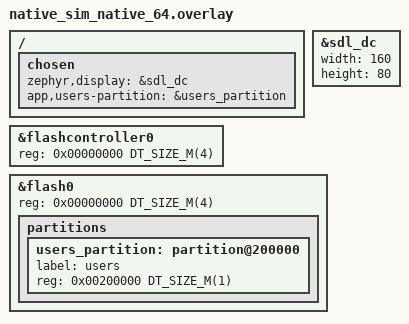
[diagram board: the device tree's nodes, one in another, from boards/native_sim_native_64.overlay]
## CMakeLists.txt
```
# SPDX-License-Identifier: Apache-2.0
cmake_minimum_required(VERSION 3.20.0)

# In-house libraries (gzm/): a Zephyr module that lives in this repository.
list(APPEND ZEPHYR_EXTRA_MODULES ${CMAKE_CURRENT_SOURCE_DIR}/../gzm)

find_package(Zephyr REQUIRED HINTS $ENV{ZEPHYR_BASE})
project(conferencia2026_demo LANGUAGES C)

target_include_directories(app PRIVATE inc)

target_sources(app PRIVATE
  src/main.c
  src/setup.c
  src/users_app.c
  src/ui_app.c
  src/images/gzm_logo_160.c
)

target_sources_ifdef(CONFIG_MCUBOOT_IMG_MANAGER app PRIVATE
  src/boot/boot.c
  src/boot/boot_shell.c
)
```

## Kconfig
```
# Copyright (c) 2026 GZM Embarcados
# SPDX-License-Identifier: Apache-2.0

mainmenu "Do Codigo ao Campo demo"

source "Kconfig.zephyr"

config APP_ADMIN_ID
	int "Default admin id (created on the first boot)"
	default 1

config APP_ADMIN_PASSWORD
	string "Default admin password (first boot only)"
	default "1234"
	help
	  Demo value, known by the Robot Framework suite. A product sets a
	  per-device password at the factory.
```

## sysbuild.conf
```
# Sysbuild configuration file.

# Enable MCUboot bootloader
SB_CONFIG_BOOTLOADER_MCUBOOT=y

# MCUboot upgrade mode: SWAP using scratch partition.
# Supports different sector sizes between slots (internal 128 KB vs
# external QSPI NOR 4 KB) and enables automatic rollback.
SB_CONFIG_MCUBOOT_MODE_SWAP_SCRATCH=y

# Signed images (ECDSA P-256). Demo key generated locally by
# tools/keys/genkeys.sh. Never commit a production key.
SB_CONFIG_BOOT_SIGNATURE_TYPE_ECDSA_P256=y
SB_CONFIG_BOOT_SIGNATURE_KEY_FILE="${APP_DIR}/../tools/keys/demo-ecdsa-p256.pem"

# Image encryption (ECIES P-256): the image stored in slot1 (external
# QSPI NOR) travels and rests encrypted; MCUboot decrypts during swap.
SB_CONFIG_BOOT_ENCRYPTION=y
SB_CONFIG_BOOT_ENCRYPTION_KEY_FILE="${APP_DIR}/../tools/keys/demo-encryption-p256.pem"
```

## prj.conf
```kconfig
CONFIG_SHELL=y
CONFIG_SHELL_STACK_SIZE=4096
CONFIG_LOG=y
CONFIG_LOG_MODE_DEFERRED=y

# === Display + LVGL ===
CONFIG_DISPLAY=y
CONFIG_LVGL=y
CONFIG_LV_CONF_MINIMAL=y
CONFIG_LV_Z_MEM_POOL_SIZE=16384
CONFIG_LV_USE_LABEL=y
CONFIG_LV_USE_IMAGE=y
CONFIG_LV_USE_BAR=y
# LV_CONF_MINIMAL ships without a theme; without one, default bg_opa is
# transparent and NOTHING gets filled (screens included). Enable the
# default theme in dark mode.
CONFIG_LV_USE_THEME_DEFAULT=y
CONFIG_LV_THEME_DEFAULT_DARK=y
CONFIG_LV_FONT_MONTSERRAT_12=y
CONFIG_LV_FONT_MONTSERRAT_14=y
CONFIG_LV_FONT_MONTSERRAT_24=y
CONFIG_LV_FONT_DEFAULT_MONTSERRAT_14=y


# === User store: gzm user_mgr on LittleFS (gzm/ module) ===
CONFIG_FLASH=y
CONFIG_FLASH_MAP=y
CONFIG_FLASH_PAGE_LAYOUT=y
CONFIG_FILE_SYSTEM=y
CONFIG_FILE_SYSTEM_LITTLEFS=y
CONFIG_FILE_SYSTEM_MKFS=y
CONFIG_PSA_CRYPTO=y
CONFIG_ENTROPY_GENERATOR=y
CONFIG_GZM_USER_MGR=y
CONFIG_GZM_USER_MGR_SHELL=y
# Product rule: at most 50 users, the default admin included
CONFIG_GZM_USER_MGR_MAX=50
# "fs ls /lfs/users", "fs cat …": look at the files behind the users
CONFIG_FILE_SYSTEM_SHELL=y
CONFIG_HEAP_MEM_POOL_SIZE=16384

# === Misc ===
CONFIG_MAIN_STACK_SIZE=8192
CONFIG_PRINTK=y
```

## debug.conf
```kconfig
# Debug options, loaded by every build (tasks "West Build" and "Native Build").
# Off by default, so the image you flash or update is the release one.
# Uncomment to debug: the next build picks the change up, no pristine needed.

# -Og instead of -Os: stepping follows the code and no <optimized out>
# CONFIG_DEBUG_OPTIMIZATIONS=y

# Thread list in the debugger (cortex-debug "rtos": "Zephyr"). Needs a gdb
# server with Zephyr support (OpenOCD, J-Link, pyOCD): the ST-LINK_gdbserver
# used here has none, so with ST-Link this option does nothing
# CONFIG_DEBUG_THREAD_INFO=y
```

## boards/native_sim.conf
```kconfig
# native_sim: LVGL UI in an SDL window on the host. No USB/MCUboot.
CONFIG_LV_COLOR_16_SWAP=n

# User store on the simulated flash (RAM-backed NOR).
CONFIG_FLASH_SIMULATOR=y
```

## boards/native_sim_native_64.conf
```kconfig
# native_sim 64-bit: LVGL UI in an SDL window on the host.
CONFIG_LV_COLOR_16_SWAP=n
# Match the LVGL 16-bit render pipeline (default ARGB8888 leaves the
# window on the transparency grid).
CONFIG_SDL_DISPLAY_DEFAULT_PIXEL_FORMAT_RGB_565=y
# Bigger window for screencasts (160x80 panel shown at 2x).
CONFIG_SDL_DISPLAY_ZOOM_PCT=200

# User store on the simulated flash (RAM-backed NOR).
CONFIG_FLASH_SIMULATOR=y
```

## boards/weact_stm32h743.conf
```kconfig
# WeAct MiniSTM32H743 specific configuration (auto-loaded by Zephyr
# alongside prj.conf when building for this board).

# Console/shell over USB CDC ACM (device stack next)
CONFIG_USB_DEVICE_STACK_NEXT=y
CONFIG_USBD_CDC_ACM_CLASS=y
CONFIG_UART_LINE_CTRL=y

# The ST7735R takes RGB565 big-endian over SPI. LVGL renders little-endian
# and byte-swaps the buffer right before flush when LV_COLOR_16_SWAP is set
# (compat hook in lv_refr.c). The board defaults it to y - keep it that way.
CONFIG_LV_COLOR_16_SWAP=y

# MCUboot integration (image state, confirm, slot info)
CONFIG_STREAM_FLASH=y
CONFIG_IMG_MANAGER=y
CONFIG_MCUBOOT_IMG_MANAGER=y
CONFIG_REBOOT=y

# Link the application at slot0 (requires --sysbuild builds)
CONFIG_USE_DT_CODE_PARTITION=y

# Keep feeding the IWDG started by MCUboot (see src/main.c)
CONFIG_WATCHDOG=y

# Keep SWD reachable while the core sleeps in the idle thread (WFI).
# Off by default outside CONFIG_DEBUG builds; without it the ST-Link cannot
# attach to the running app (no NRST wired for connect-under-reset).
CONFIG_STM32_ENABLE_DEBUG_SLEEP_STOP=y

# User store: LittleFS with 4 KB blocks (the W25Q64 sector) instead of the
# default 64 KB layout: much faster erases on every user add/delete.
CONFIG_SPI_NOR_FLASH_LAYOUT_PAGE_SIZE=4096
```

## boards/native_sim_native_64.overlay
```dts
/* Demo UI on the host: SDL display window with the panel geometry, and
 * the user store (LittleFS) on the flash simulator. The stock storage
 * partition is only 16 KB: grow the simulated flash to 4 MB and give the
 * users a 1 MB partition after the default layout. */

/ {
	chosen {
		zephyr,display = &sdl_dc;
		app,users-partition = &users_partition;
	};
};

&sdl_dc {
	width = <160>;
	height = <80>;
};

&flashcontroller0 {
	reg = <0x00000000 DT_SIZE_M(4)>;
};

&flash0 {
	reg = <0x00000000 DT_SIZE_M(4)>;

	partitions {
		users_partition: partition@200000 {
			label = "users";
			reg = <0x00200000 DT_SIZE_M(1)>;
		};
	};
};
```

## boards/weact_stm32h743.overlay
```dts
/*
 * Application overlay:
 * - user store (LittleFS) on the SPI NOR (W25Q64, storage_partition)
 * - application image linked into slot0 (MCUboot primary)
 */

/ {
	chosen {
		zephyr,code-partition = &slot0_partition;
		app,users-partition = &storage_partition;
	};
};
```

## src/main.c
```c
/* Copyright (c) 2026 GZM Embarcados
 * SPDX-License-Identifier: Apache-2.0
 */

#include <zephyr/drivers/watchdog.h>
#include <zephyr/kernel.h>
#include <lvgl.h>

#include "setup.h"

/* MCUboot starts the IWDG (20 s) and it cannot be stopped: the main loop
 * must keep feeding it. */
#if defined(CONFIG_WATCHDOG) && DT_NODE_HAS_STATUS(DT_ALIAS(watchdog0), okay)
static const struct device *const wdt = DEVICE_DT_GET(DT_ALIAS(watchdog0));
#define WDT_FEED() wdt_feed(wdt, 0)
#else
#define WDT_FEED()
#endif

int main(void)
{
	setup_init();

	while (1) {
		uint32_t sleep_ms = lv_timer_handler();

		WDT_FEED();
		k_msleep(MIN(sleep_ms, 50U));
	}

	return 0;
}
```

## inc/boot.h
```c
/* Copyright (c) 2026 GZM Embarcados
 * SPDX-License-Identifier: Apache-2.0
 */

#ifndef APP_BOOT_H_
#define APP_BOOT_H_

#ifdef __cplusplus
extern "C" {
#endif

#include <stdint.h>
#include <stdbool.h>

struct boot_slot_info {
	int slot;
	uint32_t offset;
	uint32_t size;
	uint32_t image_size;
	uint8_t version_major;
	uint8_t version_minor;
	uint16_t version_revision;
	uint32_t version_build;
	uint8_t hash[32];          /* SHA256 from the image TLV */
	char label[24];
	bool valid_header;
	bool has_hash;
	bool confirmed;            /* slot0: image confirmed */
	bool active;               /* slot0: running image */
	bool pending;              /* slot1: upgrade pending */
};

int boot_get_slot_count(void);

/** @brief Confirm the running image if it is not confirmed yet. */
void boot_check_and_confirm_image(void);

bool boot_is_image_confirmed(void);

int boot_erase_slot1(void);

/** @brief Fill @p info with header/flags/hash of the given slot. */
int boot_get_slot_info(int slot, struct boot_slot_info *info);

#ifdef __cplusplus
}
#endif

#endif /* APP_BOOT_H_ */
```

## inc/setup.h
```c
/* Copyright (c) 2026 GZM Embarcados
 * SPDX-License-Identifier: Apache-2.0
 */

#ifndef APP_SETUP_H_
#define APP_SETUP_H_

#ifdef __cplusplus
extern "C" {
#endif

/** @brief Bring up USB, the user store and the UI; a failing step is
 *  logged and boot continues. */
void setup_init(void);

#ifdef __cplusplus
}
#endif

#endif /* APP_SETUP_H_ */
```

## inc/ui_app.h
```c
/* Copyright (c) 2026 GZM Embarcados
 * SPDX-License-Identifier: Apache-2.0
 */

#ifndef APP_UI_APP_H_
#define APP_UI_APP_H_

#ifdef __cplusplus
extern "C" {
#endif

#include <stdint.h>

/**
 * Build the splash and main screens. The firmware major version picks the
 * colors: odd = white splash bar and black main screen, even = yellow.
 */
int ui_app_init(uint8_t fw_major);

#ifdef __cplusplus
}
#endif

#endif /* APP_UI_APP_H_ */
```

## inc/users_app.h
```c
/* Copyright (c) 2026 GZM Embarcados
 * SPDX-License-Identifier: Apache-2.0
 */

#ifndef APP_USERS_APP_H_
#define APP_USERS_APP_H_

#include <stdbool.h>
#include <stddef.h>

#ifdef __cplusplus
extern "C" {
#endif

/** @brief Mount LittleFS and load the user store (gzm user_mgr). */
int users_app_init(void);

bool users_app_ready(void);

/** @brief Registered users, the default admin included. */
size_t users_app_count(void);

size_t users_app_blocked(void);

#ifdef __cplusplus
}
#endif

#endif /* APP_USERS_APP_H_ */
```

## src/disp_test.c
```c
/* Copyright (c) 2026 GZM Embarcados
 * SPDX-License-Identifier: Apache-2.0
 *
 * Fills the panel through the display API, bypassing LVGL: separates panel
 * or byte-order problems from LVGL rendering problems.
 */

#include <zephyr/device.h>
#include <zephyr/drivers/display.h>
#include <zephyr/shell/shell.h>
#include <zephyr/sys/byteorder.h>

#include <stdlib.h>
#include <string.h>

#define DISP_W 160
#define DISP_H 80
#define STRIP_H 8

static uint16_t strip[DISP_W * STRIP_H];

struct color_map {
	const char *name;
	uint16_t rgb565; /* natural value, R in the top bits */
};

static const struct color_map colors[] = {
	{ "red",   0xF800 }, { "green", 0x07E0 }, { "blue",  0x001F },
	{ "white", 0xFFFF }, { "black", 0x0000 }, { "gray",  0x39C7 },
};

static int fill(const struct shell *shell, const char *name, bool swap)
{
	const struct device *disp = DEVICE_DT_GET(DT_CHOSEN(zephyr_display));
	const struct color_map *c = NULL;

	for (size_t i = 0; i < ARRAY_SIZE(colors); i++) {
		if (strcmp(name, colors[i].name) == 0) {
			c = &colors[i];
			break;
		}
	}
	if (c == NULL) {
		shell_error(shell, "colors: red green blue white black gray");
		return -EINVAL;
	}
	if (!device_is_ready(disp)) {
		shell_error(shell, "display not ready");
		return -ENODEV;
	}

	/* Panel wire order is big-endian; "fillswap" sends CPU-native LE. */
	uint16_t v = swap ? c->rgb565 : sys_cpu_to_be16(c->rgb565);

	for (size_t i = 0; i < ARRAY_SIZE(strip); i++) {
		strip[i] = v;
	}

	struct display_buffer_descriptor desc = {
		.buf_size = sizeof(strip),
		.width = DISP_W,
		.height = STRIP_H,
		.pitch = DISP_W,
	};

	for (int y = 0; y < DISP_H; y += STRIP_H) {
		int ret = display_write(disp, 0, y, &desc, strip);

		if (ret) {
			shell_error(shell, "display_write: %d", ret);
			return ret;
		}
	}

	shell_print(shell, "filled %s%s (0x%04x)", name,
		    swap ? " (swapped)" : "", v);
	return 0;
}

static int cmd_fill(const struct shell *shell, size_t argc, char **argv)
{
	if (argc != 2) {
		shell_error(shell, "Usage: disp fill <color>");
		return -EINVAL;
	}
	return fill(shell, argv[1], false);
}

static int cmd_fillswap(const struct shell *shell, size_t argc, char **argv)
{
	if (argc != 2) {
		shell_error(shell, "Usage: disp fillswap <color>");
		return -EINVAL;
	}
	return fill(shell, argv[1], true);
}

SHELL_STATIC_SUBCMD_SET_CREATE(sub_disp,
	SHELL_CMD(fill, NULL, "Fill screen via display API (no LVGL)", cmd_fill),
	SHELL_CMD(fillswap, NULL, "Fill with byte-swapped color", cmd_fillswap),
	SHELL_SUBCMD_SET_END);

SHELL_CMD_REGISTER(disp, &sub_disp, "Raw display tests", NULL);
```

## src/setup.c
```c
/* Copyright (c) 2026 GZM Embarcados
 * SPDX-License-Identifier: Apache-2.0
 */

#include <zephyr/device.h>
#include <zephyr/kernel.h>
#include <zephyr/usb/usbd.h>

#include <app_version.h>

#include "setup.h"
#include "ui_app.h"
#include "users_app.h"

#include <zephyr/logging/log.h>
LOG_MODULE_REGISTER(setup, CONFIG_LOG_DEFAULT_LEVEL);

#ifdef CONFIG_USB_DEVICE_STACK_NEXT
USBD_DEVICE_DEFINE(usbd_device,
		   DEVICE_DT_GET(DT_NODELABEL(usbotg_fs)),
		   0x1209, 0x0001);

USBD_DESC_LANG_DEFINE(usb_lang);
USBD_DESC_MANUFACTURER_DEFINE(usb_mfr, "GZM Embedded Systems");
USBD_DESC_PRODUCT_DEFINE(usb_product, "Do Codigo ao Campo Demo");
USBD_DESC_CONFIG_DEFINE(usb_fs_cfg_desc, "FS Configuration");

USBD_CONFIGURATION_DEFINE(usb_fs_config, USB_SCD_SELF_POWERED, 100, &usb_fs_cfg_desc);
#endif /* CONFIG_USB_DEVICE_STACK_NEXT */

static void setup_sanity_init(void)
{
	printk("Do Codigo ao Campo demo v%s\r\n", APP_VERSION_STRING);
}

static int setup_usb_init(void)
{
#ifndef CONFIG_USB_DEVICE_STACK_NEXT
	return 0;
#else
	int ret;

	ret = usbd_add_descriptor(&usbd_device, &usb_lang);
	if (ret) {
		LOG_ERR("USB lang descriptor: %d", ret);
		return ret;
	}

	ret = usbd_add_descriptor(&usbd_device, &usb_mfr);
	if (ret) {
		LOG_ERR("USB mfr descriptor: %d", ret);
		return ret;
	}

	ret = usbd_add_descriptor(&usbd_device, &usb_product);
	if (ret) {
		LOG_ERR("USB product descriptor: %d", ret);
		return ret;
	}

	ret = usbd_add_configuration(&usbd_device, USBD_SPEED_FS, &usb_fs_config);
	if (ret) {
		LOG_ERR("USB FS config: %d", ret);
		return ret;
	}

	ret = usbd_register_all_classes(&usbd_device, USBD_SPEED_FS, 1, NULL);
	if (ret) {
		LOG_ERR("USB register classes: %d", ret);
		return ret;
	}

	usbd_device_set_code_triple(&usbd_device, USBD_SPEED_FS,
				    USB_BCC_MISCELLANEOUS, 0x02, 0x01);

	ret = usbd_init(&usbd_device);
	if (ret) {
		LOG_ERR("usbd_init: %d", ret);
		return ret;
	}

	ret = usbd_enable(&usbd_device);
	if (ret) {
		LOG_ERR("usbd_enable: %d", ret);
		return ret;
	}

	return 0;
#endif /* CONFIG_USB_DEVICE_STACK_NEXT */
}

void setup_init(void)
{
	int ret;

	setup_sanity_init();

	ret = setup_usb_init();
	if (ret) {
		LOG_ERR("USB console init failed: %d", ret);
	}

	ret = users_app_init();
	if (ret) {
		LOG_ERR("users_app init failed: %d", ret);
	}

	ret = ui_app_init(APP_VERSION_MAJOR);
	if (ret) {
		LOG_ERR("ui_app init failed: %d", ret);
	}

	LOG_INF("setup done");
}
```

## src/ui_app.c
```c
/* Copyright (c) 2026 GZM Embarcados
 * SPDX-License-Identifier: Apache-2.0
 */

#include <lvgl.h>
#include <stdio.h>
#include <zephyr/device.h>
#include <zephyr/drivers/display.h>
#include <zephyr/drivers/gpio.h>
#include <string.h>
#include <zephyr/shell/shell.h>

#include <app_version.h>

#include "boot.h"
#include "ui_app.h"
#include "users_app.h"

#include <zephyr/logging/log.h>
LOG_MODULE_REGISTER(ui_app, CONFIG_LOG_DEFAULT_LEVEL);

#define UI_REFRESH_MS 200
#define UI_SPLASH_MS  3000

LV_IMAGE_DECLARE(gzm_logo_160);

static lv_obj_t *label_users;
static lv_obj_t *label_blocked;
static lv_obj_t *label_version;
static lv_obj_t *splash_bar;
static uint32_t splash_start;

#if DT_NODE_HAS_PROP(DT_PATH(zephyr_user), backlight_gpios)
static const struct gpio_dt_spec backlight =
	GPIO_DT_SPEC_GET(DT_PATH(zephyr_user), backlight_gpios);
#endif

/* Shell requests are applied from the LVGL timer context: LVGL is not
 * thread-safe. */
enum ui_request { UI_REQ_NONE, UI_REQ_PATTERN, UI_REQ_LOGO, UI_REQ_MAIN };
static volatile enum ui_request ui_request;

static void ui_main_create(void);

/* The firmware major version picks the colors (see ui_app_init), so an
 * update between an odd and an even version is visible at a glance. On
 * yellow the texts switch to dark tones to stay readable. */
struct ui_theme {
	uint32_t splash_bar;
	uint32_t main_bg;
	uint32_t title;
	uint32_t caption;
	uint32_t value;
	uint32_t value_full;
	uint32_t blocked;
	uint32_t confirmed;
	uint32_t testing;
};

static const struct ui_theme theme_odd = {
	.splash_bar = 0xffffff, .main_bg = 0x101418, .title = 0x80d8ff,
	.caption = 0x9e9e9e, .value = 0xffffff, .value_full = 0xff8a80,
	.blocked = 0xffab00, .confirmed = 0x00c853, .testing = 0xffab00,
};

static const struct ui_theme theme_even = {
	.splash_bar = 0xffd600, .main_bg = 0xffd600, .title = 0x0d47a1,
	.caption = 0x424242, .value = 0x101418, .value_full = 0xb71c1c,
	.blocked = 0xbf360c, .confirmed = 0x1b5e20, .testing = 0xbf360c,
};

static const struct ui_theme *theme = &theme_odd;

static void ui_refresh_cb(lv_timer_t *timer)
{
	ARG_UNUSED(timer);
	char text[32];

	if (label_users == NULL || label_blocked == NULL || label_version == NULL) {
		return;
	}

	if (users_app_ready()) {
		size_t n = users_app_count();
		size_t blocked = users_app_blocked();

		snprintf(text, sizeof(text), "%zu/%d", n, CONFIG_GZM_USER_MGR_MAX);
		lv_label_set_text(label_users, text);
		/* Full store: the next "user add" is refused (-ENOSPC). */
		lv_obj_set_style_text_color(label_users,
					    lv_color_hex(n >= CONFIG_GZM_USER_MGR_MAX
								 ? theme->value_full
								 : theme->value),
					    LV_PART_MAIN);
		snprintf(text, sizeof(text), "%zu", blocked);
		lv_label_set_text(label_blocked, text);
	} else {
		lv_label_set_text(label_users, "--");
		lv_label_set_text(label_blocked, "--");
	}

#ifdef CONFIG_MCUBOOT_IMG_MANAGER
	/* Reading the state goes to flash: once confirmed it cannot revert until
	 * the next boot, so stop polling; while in test, poll once per second. */
	static bool confirmed;
	static uint32_t polls;

	if (!confirmed && (polls++ % (1000 / UI_REFRESH_MS)) == 0) {
		confirmed = boot_is_image_confirmed();
	}
	const char *state = confirmed ? "OK" : "TEST";
	lv_color_t color = lv_color_hex(confirmed ? theme->confirmed : theme->testing);
#else
	const char *state = "SIM";
	lv_color_t color = lv_color_hex(theme->title);
#endif

	snprintf(text, sizeof(text), "v%s %s", APP_VERSION_STRING, state);
	lv_label_set_text(label_version, text);
	lv_obj_set_style_text_color(label_version, color, LV_PART_MAIN);
}

static void ui_main_create(void)
{
	lv_obj_t *screen = lv_screen_active();

	lv_obj_set_style_bg_opa(screen, LV_OPA_COVER, LV_PART_MAIN);

	lv_obj_t *title = lv_label_create(screen);

	lv_label_set_text(title, "DO CODIGO AO CAMPO");
	lv_obj_set_style_text_font(title, &lv_font_montserrat_12, LV_PART_MAIN);
	lv_obj_set_style_text_color(title, lv_color_hex(theme->title), LV_PART_MAIN);
	lv_obj_align(title, LV_ALIGN_TOP_MID, 0, 2);

	lv_obj_t *cap_users = lv_label_create(screen);

	lv_label_set_text(cap_users, "usuarios");
	lv_obj_set_style_text_font(cap_users, &lv_font_montserrat_12, LV_PART_MAIN);
	lv_obj_set_style_text_color(cap_users, lv_color_hex(theme->caption), LV_PART_MAIN);
	lv_obj_align(cap_users, LV_ALIGN_LEFT_MID, 8, -16);

	label_users = lv_label_create(screen);
	lv_label_set_text(label_users, "--");
	lv_obj_set_style_text_font(label_users, &lv_font_montserrat_24, LV_PART_MAIN);
	lv_obj_set_style_text_color(label_users, lv_color_hex(theme->value), LV_PART_MAIN);
	lv_obj_align(label_users, LV_ALIGN_LEFT_MID, 8, 6);

	lv_obj_t *cap_blocked = lv_label_create(screen);

	lv_label_set_text(cap_blocked, "bloqueados");
	lv_obj_set_style_text_font(cap_blocked, &lv_font_montserrat_12, LV_PART_MAIN);
	lv_obj_set_style_text_color(cap_blocked, lv_color_hex(theme->caption), LV_PART_MAIN);
	lv_obj_align(cap_blocked, LV_ALIGN_RIGHT_MID, -8, -16);

	label_blocked = lv_label_create(screen);
	lv_label_set_text(label_blocked, "--");
	lv_obj_set_style_text_font(label_blocked, &lv_font_montserrat_24, LV_PART_MAIN);
	lv_obj_set_style_text_color(label_blocked, lv_color_hex(theme->blocked), LV_PART_MAIN);
	lv_obj_align(label_blocked, LV_ALIGN_RIGHT_MID, -8, 6);

	label_version = lv_label_create(screen);
	lv_label_set_text(label_version, "v" APP_VERSION_STRING);
	lv_obj_align(label_version, LV_ALIGN_BOTTOM_MID, 0, -2);

	lv_timer_create(ui_refresh_cb, UI_REFRESH_MS, NULL);
}

/* R/G/B/W bars: any panel color transform (byte swap, BGR, inversion)
 * shows up unambiguously. */
static void ui_pattern_create(void)
{
	static const struct { uint32_t color; const char *tag; } bars[] = {
		{ 0xff0000, "R" }, { 0x00ff00, "G" },
		{ 0x0000ff, "B" }, { 0xffffff, "W" },
	};
	lv_obj_t *screen = lv_screen_active();

	lv_obj_set_style_bg_color(screen, lv_color_hex(0x000000), LV_PART_MAIN);
	lv_obj_set_style_bg_opa(screen, LV_OPA_COVER, LV_PART_MAIN);

	for (int i = 0; i < 4; i++) {
		lv_obj_t *rect = lv_obj_create(screen);

		lv_obj_set_size(rect, 40, 50);
		lv_obj_set_pos(rect, i * 40, 0);
		lv_obj_set_style_bg_color(rect, lv_color_hex(bars[i].color),
					  LV_PART_MAIN);
		lv_obj_set_style_bg_opa(rect, LV_OPA_COVER, LV_PART_MAIN);
		lv_obj_set_style_radius(rect, 0, LV_PART_MAIN);
		lv_obj_set_style_border_width(rect, 0, LV_PART_MAIN);

		lv_obj_t *tag = lv_label_create(rect);

		lv_label_set_text(tag, bars[i].tag);
		lv_obj_set_style_text_color(tag, lv_color_hex(0x000000), LV_PART_MAIN);
		lv_obj_center(tag);
	}

	lv_obj_t *strip = lv_obj_create(screen);

	lv_obj_set_size(strip, 160, 16);
	lv_obj_set_pos(strip, 0, 52);
	lv_obj_set_style_bg_color(strip, lv_color_hex(0x383838), LV_PART_MAIN);
	lv_obj_set_style_bg_opa(strip, LV_OPA_COVER, LV_PART_MAIN);
	lv_obj_set_style_radius(strip, 0, LV_PART_MAIN);
	lv_obj_set_style_border_width(strip, 0, LV_PART_MAIN);

	lv_obj_t *note = lv_label_create(screen);

	lv_label_set_text(note, "R G B W + cinza");
	lv_obj_set_style_text_color(note, lv_color_hex(0xffffff), LV_PART_MAIN);
	lv_obj_align(note, LV_ALIGN_BOTTOM_MID, 0, 0);
}

static void ui_logo_create(void)
{
	lv_obj_t *screen = lv_screen_active();

	lv_obj_set_style_bg_color(screen, lv_color_hex(0x383838), LV_PART_MAIN);
	lv_obj_set_style_bg_opa(screen, LV_OPA_COVER, LV_PART_MAIN);

	lv_obj_t *logo = lv_image_create(screen);

	lv_image_set_src(logo, &gzm_logo_160);
	lv_obj_center(logo);
}

static void ui_request_cb(lv_timer_t *timer)
{
	ARG_UNUSED(timer);
	enum ui_request req = ui_request;

	if (req == UI_REQ_NONE) {
		return;
	}
	ui_request = UI_REQ_NONE;

	label_users = NULL;
	label_blocked = NULL;
	label_version = NULL;
	lv_obj_clean(lv_screen_active());

	switch (req) {
	case UI_REQ_PATTERN:
		ui_pattern_create();
		break;
	case UI_REQ_LOGO:
		ui_logo_create();
		break;
	default:
		lv_obj_set_style_bg_color(lv_screen_active(), lv_color_hex(theme->main_bg),
					  LV_PART_MAIN);
		lv_obj_set_style_bg_opa(lv_screen_active(), LV_OPA_COVER, LV_PART_MAIN);
		ui_main_create();
		break;
	}
}

static int cmd_ui(const struct shell *shell, size_t argc, char **argv)
{
	if (argc != 2) {
		shell_error(shell, "Usage: ui <pattern|logo|main>");
		return -EINVAL;
	}
	if (strcmp(argv[1], "pattern") == 0) {
		ui_request = UI_REQ_PATTERN;
	} else if (strcmp(argv[1], "logo") == 0) {
		ui_request = UI_REQ_LOGO;
	} else {
		ui_request = UI_REQ_MAIN;
	}
	shell_print(shell, "ui: switching to %s", argv[1]);
	return 0;
}

SHELL_CMD_REGISTER(ui, NULL, "Switch UI screen (pattern|logo|main)", cmd_ui);

static void splash_tick_cb(lv_timer_t *timer)
{
	uint32_t elapsed = lv_tick_elaps(splash_start);
	int32_t pct = (int32_t)((elapsed * 100U) / UI_SPLASH_MS);

	if (pct >= 100) {
		lv_bar_set_value(splash_bar, 100, LV_ANIM_OFF);
		lv_timer_delete(timer);
		lv_obj_clean(lv_screen_active());
		lv_obj_set_style_bg_color(lv_screen_active(), lv_color_hex(theme->main_bg),
					  LV_PART_MAIN);
		lv_obj_set_style_bg_opa(lv_screen_active(), LV_OPA_COVER, LV_PART_MAIN);
		ui_main_create();
		return;
	}

	lv_bar_set_value(splash_bar, pct, LV_ANIM_OFF);
}

int ui_app_init(uint8_t fw_major)
{
	lv_obj_t *screen = lv_screen_active();

	theme = (fw_major % 2) ? &theme_odd : &theme_even;

	lv_obj_set_style_bg_color(screen, lv_color_hex(0x383838), LV_PART_MAIN);
	lv_obj_set_style_bg_opa(screen, LV_OPA_COVER, LV_PART_MAIN);

	lv_obj_t *logo = lv_image_create(screen);

	lv_image_set_src(logo, &gzm_logo_160);
	lv_obj_align(logo, LV_ALIGN_TOP_MID, 0, 2);

	splash_bar = lv_bar_create(screen);
	lv_obj_set_size(splash_bar, 140, 8);
	lv_obj_align(splash_bar, LV_ALIGN_BOTTOM_MID, 0, -6);
	lv_bar_set_range(splash_bar, 0, 100);
	lv_bar_set_value(splash_bar, 0, LV_ANIM_OFF);
	lv_obj_set_style_bg_opa(splash_bar, LV_OPA_COVER, LV_PART_MAIN);
	lv_obj_set_style_bg_opa(splash_bar, LV_OPA_COVER, LV_PART_INDICATOR);
	lv_obj_set_style_bg_color(splash_bar, lv_color_hex(0x2a2a2a), LV_PART_MAIN);
	lv_obj_set_style_radius(splash_bar, 4, LV_PART_MAIN);
	lv_obj_set_style_bg_color(splash_bar, lv_color_hex(theme->splash_bar),
				  LV_PART_INDICATOR);
	lv_obj_set_style_radius(splash_bar, 4, LV_PART_INDICATOR);

	splash_start = lv_tick_get();
	lv_timer_create(splash_tick_cb, 30, NULL);
	lv_timer_create(ui_request_cb, 100, NULL);

	/* Draw now so the backlight never shows a partial frame. The SDL
	 * display on native_sim stays blank until blanking is turned off. */
	lv_refr_now(NULL);
	display_blanking_off(DEVICE_DT_GET(DT_CHOSEN(zephyr_display)));

#if DT_NODE_HAS_PROP(DT_PATH(zephyr_user), backlight_gpios)
	if (gpio_is_ready_dt(&backlight)) {
		gpio_pin_configure_dt(&backlight, GPIO_OUTPUT_ACTIVE);
	}
#endif

	return 0;
}
```

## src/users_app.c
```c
/* Copyright (c) 2026 GZM Embarcados
 * SPDX-License-Identifier: Apache-2.0
 *
 * User store of the demo: the gzm user_mgr library on LittleFS. The
 * partition comes from the devicetree (chosen app,users-partition): the
 * SPI NOR on the board, the flash simulator on native_sim.
 */

#include <zephyr/fs/fs.h>
#include <zephyr/fs/littlefs.h>
#include <zephyr/storage/flash_map.h>

#include <gzm/fs_mgr.h>
#include <gzm/user_mgr.h>

#include "users_app.h"

#include <zephyr/logging/log.h>
LOG_MODULE_REGISTER(users_app, CONFIG_LOG_DEFAULT_LEVEL);

#define USERS_PARTITION DT_CHOSEN(app_users_partition)
#define USERS_MNT       "/lfs"
#define USERS_DIR       USERS_MNT "/users"

FS_LITTLEFS_DECLARE_DEFAULT_CONFIG(users_lfs);

static struct fs_mount_t users_mnt = {
	.type = FS_LITTLEFS,
	.fs_data = &users_lfs,
	.storage_dev = (void *)DT_FIXED_PARTITION_ID(USERS_PARTITION),
	.mnt_point = USERS_MNT,
};

int users_app_init(void)
{
	int ret;

	ret = fs_mgr_init(&users_mnt);
	if (ret) {
		LOG_ERR("LittleFS on %s: %d", USERS_MNT, ret);
		return ret;
	}

	ret = user_mgr_init(USERS_DIR);
	if (ret) {
		LOG_ERR("user_mgr_init: %d", ret);
		return ret;
	}

	/* Only on an empty store: the first boot, or after a format. */
	ret = user_mgr_create_default_admin(CONFIG_APP_ADMIN_ID, CONFIG_APP_ADMIN_PASSWORD,
					    ACC_LEVEL_ADMIN);
	if (ret == 0) {
		LOG_INF("default admin %d created", CONFIG_APP_ADMIN_ID);
	} else if (ret != -EEXIST) {
		LOG_ERR("default admin: %d", ret);
	}

	LOG_INF("%zu users (%zu blocked), max %d", user_mgr_count(), user_mgr_count_blocked(),
		CONFIG_GZM_USER_MGR_MAX);
	return 0;
}

bool users_app_ready(void)
{
	return user_mgr_is_ready();
}

size_t users_app_count(void)
{
	return user_mgr_count();
}

size_t users_app_blocked(void)
{
	return user_mgr_count_blocked();
}
```
